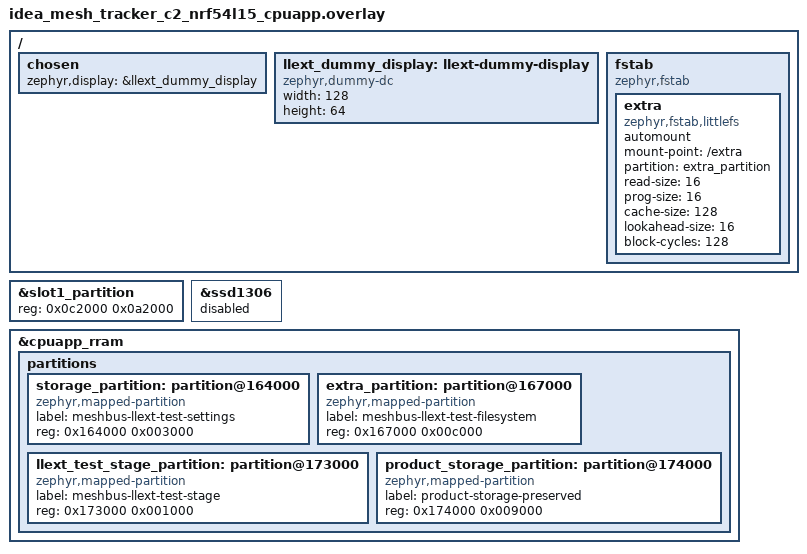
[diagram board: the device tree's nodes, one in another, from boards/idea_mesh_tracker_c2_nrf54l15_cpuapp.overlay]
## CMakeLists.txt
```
cmake_minimum_required(VERSION 3.20.0)

find_package(Zephyr REQUIRED HINTS $ENV{ZEPHYR_BASE})
project(mbs_llext_service_dut_test)

target_sources(app PRIVATE src/test_service_dut.c)
target_include_directories(app PRIVATE ../src)

set(llext_targets)
set(llext_outputs)


set(app_bin ${PROJECT_BINARY_DIR}/llext/mbs_app.mba)
set(app_inc ${ZEPHYR_BINARY_DIR}/include/generated/mbs_app.inc)
set(bad_symbol_app_bin ${PROJECT_BINARY_DIR}/llext/mbs_badsymapp.mba)
set(bad_symbol_app_inc ${ZEPHYR_BINARY_DIR}/include/generated/mbs_badsymapp.inc)

add_llext_target(mbs_app_ext
	OUTPUT ${app_bin}
	SOURCES ${CMAKE_CURRENT_SOURCE_DIR}/../src/app_ext.c
)
add_llext_target(mbs_badsymapp_ext
	OUTPUT ${bad_symbol_app_bin}
	SOURCES ${CMAKE_CURRENT_SOURCE_DIR}/../src/app_bad_symbol_ext.c
)

list(APPEND llext_targets mbs_app_ext mbs_badsymapp_ext)
list(APPEND llext_outputs ${app_bin} ${bad_symbol_app_bin})

generate_inc_file_for_target(app ${app_bin} ${app_inc})
generate_inc_file_for_target(app ${bad_symbol_app_bin} ${bad_symbol_app_inc})

foreach(llext_target ${llext_targets})
	if(TARGET ${llext_target}_llext_lib AND TARGET mbs_proto)
		add_dependencies(${llext_target}_llext_lib mbs_proto)
	endif()
endforeach()

foreach(ext ${llext_outputs})
	add_custom_command(
		OUTPUT ${ext}
		APPEND
		COMMAND ${CMAKE_OBJCOPY}
			--set-section-flags
			.meshbus.llext.meta=contents,readonly
			${ext}
	)
endforeach()
```

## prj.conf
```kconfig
# SPDX-FileCopyrightText: FoBE Studio
# SPDX-License-Identifier: Apache-2.0

CONFIG_ZTEST=y
CONFIG_ASSERT=y
CONFIG_LOG=y
CONFIG_LOG_MODE_IMMEDIATE=y

CONFIG_USERSPACE=n
CONFIG_MPU=n
CONFIG_ARM_MPU=n

CONFIG_MBS=y
CONFIG_MBS_LLEXT=y
CONFIG_MBS_LLEXT_DEFAULT_ENABLED=y
CONFIG_MBS_LLEXT_DYNAMIC_HEAP_MARGIN_PERCENT=5
CONFIG_MBS_LLEXT_TOTAL_HEAP_MAX_SIZE=98304

CONFIG_LLEXT=y
CONFIG_LLEXT_HEAP_DYNAMIC=y
CONFIG_LLEXT_SHELL=n

CONFIG_FILE_SYSTEM=y
CONFIG_FILE_SYSTEM_LITTLEFS=y
CONFIG_FS_LITTLEFS_FMP_DEV=y
CONFIG_FLASH=y
CONFIG_FLASH_MAP=y
CONFIG_FLASH_PAGE_LAYOUT=y

CONFIG_SETTINGS=y
CONFIG_SETTINGS_ZMS=y
CONFIG_SETTINGS_ZMS_LL_CACHE=y
CONFIG_SETTINGS_ZMS_LL_CACHE_SIZE=64
CONFIG_ZMS=y
CONFIG_ZMS_LOOKUP_CACHE=y
CONFIG_ZMS_LOOKUP_CACHE_SIZE=64
CONFIG_ZMS_LOOKUP_CACHE_FOR_SETTINGS=y

CONFIG_ZBUS_PRIORITY_BOOST=n
CONFIG_ZBUS_RUNTIME_OBSERVERS=y

CONFIG_HEAP_MEM_POOL_SIZE=98304
CONFIG_MAIN_STACK_SIZE=4096
CONFIG_SYSTEM_WORKQUEUE_STACK_SIZE=4096
CONFIG_ZTEST_STACK_SIZE=6144
CONFIG_THREAD_STACK_INFO=y
```

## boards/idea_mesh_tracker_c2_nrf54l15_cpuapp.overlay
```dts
/* Dedicated validation-device layout. See README.rst before flashing. */

/delete-node/ &storage_partition;

&slot1_partition {
	reg = <0x0c2000 0x0a2000>;
};

/* App-mode tests need ZUI types but do not exercise the physical display. */
&ssd1306 {
	status = "disabled";
};

&cpuapp_rram {
	partitions {
		storage_partition: partition@164000 {
			compatible = "zephyr,mapped-partition";
			label = "meshbus-llext-test-settings";
			reg = <0x164000 0x003000>;
		};

		extra_partition: partition@167000 {
			compatible = "zephyr,mapped-partition";
			label = "meshbus-llext-test-filesystem";
			reg = <0x167000 0x00c000>;
		};

		llext_test_stage_partition: partition@173000 {
			compatible = "zephyr,mapped-partition";
			label = "meshbus-llext-test-stage";
			reg = <0x173000 0x001000>;
		};

		product_storage_partition: partition@174000 {
			compatible = "zephyr,mapped-partition";
			label = "product-storage-preserved";
			reg = <0x174000 0x009000>;
		};
	};
};

/ {
	chosen {
		zephyr,display = &llext_dummy_display;
	};

	llext_dummy_display: llext-dummy-display {
		compatible = "zephyr,dummy-dc";
		width = <128>;
		height = <64>;
	};

	fstab: fstab {
		compatible = "zephyr,fstab";
		extra: extra {
			compatible = "zephyr,fstab,littlefs";
			automount;
			mount-point = "/extra";
			partition = <&extra_partition>;
			read-size = <16>;
			prog-size = <16>;
			cache-size = <128>;
			lookahead-size = <16>;
			block-cycles = <128>;
		};
	};
};
```

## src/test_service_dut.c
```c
/* SPDX-License-Identifier: Apache-2.0 */
/*
 * Copyright (c) 2026 FoBE Studio
 */

#include <errno.h>
#include <stdint.h>
#include <string.h>

#include <zephyr/devicetree.h>
#include <zephyr/fs/fs.h>
#include <zephyr/init.h>
#include <zephyr/kernel.h>
#include <zephyr/llext/symbol.h>
#include <llext/llext.h>
#include <zephyr/storage/flash_map.h>
#include <zephyr/sys/atomic.h>
#include <zephyr/ztest.h>

#include "app_api.h"

/* Mesh Probe R2 real-storage and real-loader service-DUT coverage. */

#define SETTINGS_PARTITION_NODE DT_NODELABEL(storage_partition)
#define EXTRA_PARTITION_NODE    DT_NODELABEL(extra_partition)
#define STAGE_PARTITION_NODE    DT_NODELABEL(llext_test_stage_partition)
#define PRODUCT_PARTITION_NODE  DT_NODELABEL(product_storage_partition)
#define SLOT0_PARTITION_NODE    DT_NODELABEL(slot0_partition)
#define SLOT1_PARTITION_NODE    DT_NODELABEL(slot1_partition)
#define RRAM_NODE               DT_MEM_FROM_PARTITION(EXTRA_PARTITION_NODE)

#define PARTITION_START(node_id) DT_REG_ADDR(node_id)
#define PARTITION_END(node_id)   (DT_REG_ADDR(node_id) + DT_REG_SIZE(node_id))
#define TEST_STAGE_MAGIC         0x4d424c58U
#define TEST_STAGE_PREPARED      1U
#define TEST_APP_ID              "mbs_app"
#define TEST_APP_PATH            "/extra/apps/mbs_app.mba"
#define BAD_APP_PATH             "/extra/apps/mbs_badsymapp.mba"

struct test_stage_record {
	uint32_t magic;
	uint32_t phase;
	uint32_t inverse;
	uint32_t reserved;
};

static struct test_stage_record test_stage;
static int test_storage_prepare_rc;
static atomic_t app_count;

BUILD_ASSERT(!IS_ENABLED(CONFIG_FLASH_SIMULATOR), "Mesh Probe R2 scenario must use real RRAM");
BUILD_ASSERT(DT_NODE_HAS_STATUS(SETTINGS_PARTITION_NODE, okay), "test settings missing");
BUILD_ASSERT(DT_NODE_HAS_STATUS(EXTRA_PARTITION_NODE, okay), "test filesystem missing");
BUILD_ASSERT(DT_NODE_HAS_STATUS(STAGE_PARTITION_NODE, okay), "test stage missing");
BUILD_ASSERT(DT_NODE_HAS_STATUS(PRODUCT_PARTITION_NODE, okay), "product guard missing");
BUILD_ASSERT(DT_REG_ADDR(SETTINGS_PARTITION_NODE) == 0x164000, "wrong test settings base");
BUILD_ASSERT(DT_REG_SIZE(SETTINGS_PARTITION_NODE) == 0x3000, "wrong test settings size");
BUILD_ASSERT(DT_REG_ADDR(EXTRA_PARTITION_NODE) == 0x167000, "wrong test FS base");
BUILD_ASSERT(DT_REG_SIZE(EXTRA_PARTITION_NODE) == 0xc000, "wrong test FS size");
BUILD_ASSERT(DT_REG_ADDR(STAGE_PARTITION_NODE) == 0x173000, "wrong stage base");
BUILD_ASSERT(DT_REG_SIZE(STAGE_PARTITION_NODE) == 0x1000, "wrong stage size");
BUILD_ASSERT(DT_REG_ADDR(PRODUCT_PARTITION_NODE) == 0x174000, "wrong product storage base");
BUILD_ASSERT(DT_REG_SIZE(PRODUCT_PARTITION_NODE) == 0x9000, "wrong product storage size");
BUILD_ASSERT(DT_PROP(RRAM_NODE, erase_block_size) == 4096, "unexpected erase alignment");
BUILD_ASSERT(DT_PROP(RRAM_NODE, write_block_size) == 16, "unexpected write alignment");
BUILD_ASSERT((sizeof(struct test_stage_record) % DT_PROP(RRAM_NODE, write_block_size)) == 0,
	     "test stage record is not write aligned");
BUILD_ASSERT(PARTITION_END(SLOT0_PARTITION_NODE) <= PARTITION_START(SLOT1_PARTITION_NODE),
	     "slot0 overlaps slot1");
BUILD_ASSERT(PARTITION_END(SLOT1_PARTITION_NODE) <= PARTITION_START(SETTINGS_PARTITION_NODE),
	     "slot1 overlaps test settings");
BUILD_ASSERT(PARTITION_END(SETTINGS_PARTITION_NODE) <= PARTITION_START(EXTRA_PARTITION_NODE),
	     "test settings overlaps filesystem");
BUILD_ASSERT(PARTITION_END(EXTRA_PARTITION_NODE) <= PARTITION_START(STAGE_PARTITION_NODE),
	     "test filesystem overlaps stage");
BUILD_ASSERT(PARTITION_END(STAGE_PARTITION_NODE) <= PARTITION_START(PRODUCT_PARTITION_NODE),
	     "stage overlaps product storage");
BUILD_ASSERT(PARTITION_END(PRODUCT_PARTITION_NODE) <= DT_REG_SIZE(RRAM_NODE),
	     "product storage exceeds CPUAPP RRAM");

int mbs_llext_test_hook(int event)
{
	switch (event) {
	case MBS_LLEXT_TEST_EVT_APP:
		atomic_inc(&app_count);
		return 0;
	default:
		return -EINVAL;
	}
}
EXPORT_SYMBOL(mbs_llext_test_hook);

static const uint8_t app_ext[] __aligned(4) = {
#include "mbs_app.inc"
};
static const uint8_t bad_symbol_app_ext[] __aligned(4) = {
#include "mbs_badsymapp.inc"
};

static uint32_t elapsed_us(uint64_t started)
{
	return (uint32_t)k_cyc_to_us_floor64(k_cycle_get_64() - started);
}

static int stage_write(void)
{
	const struct flash_area *area = NULL;
	struct test_stage_record next = {
		.magic = TEST_STAGE_MAGIC,
		.phase = TEST_STAGE_PREPARED,
		.inverse = ~TEST_STAGE_PREPARED,
	};
	int rc = flash_area_open(DT_FIXED_PARTITION_ID(STAGE_PARTITION_NODE), &area);

	if (rc == 0) {
		rc = flash_area_flatten(area, 0, area->fa_size);
	}
	if (rc == 0) {
		rc = flash_area_write(area, 0, &next, sizeof(next));
	}
	if (area != NULL) {
		flash_area_close(area);
	}
	if (rc == 0) {
		test_stage = next;
	}
	return rc;
}

static int stage_erase(void)
{
	const struct flash_area *area;
	int rc = flash_area_open(DT_FIXED_PARTITION_ID(STAGE_PARTITION_NODE), &area);

	if (rc == 0) {
		rc = flash_area_flatten(area, 0, area->fa_size);
		flash_area_close(area);
	}
	return rc;
}

static int flatten_partition(int partition_id)
{
	const struct flash_area *area;
	int rc = flash_area_open(partition_id, &area);

	if (rc == 0) {
		rc = flash_area_flatten(area, 0, area->fa_size);
		flash_area_close(area);
	}
	return rc;
}

static int llext_test_storage_prepare(void)
{
	int rc;

	rc = flatten_partition(DT_FIXED_PARTITION_ID(SETTINGS_PARTITION_NODE));
	if (rc == 0) {
		rc = flatten_partition(DT_FIXED_PARTITION_ID(EXTRA_PARTITION_NODE));
	}
	if (rc == 0) {
		rc = stage_write();
	}
	test_storage_prepare_rc = rc;
	return 0;
}

SYS_INIT(llext_test_storage_prepare, POST_KERNEL, 98);

static int write_file(const char *path, const uint8_t *data, size_t data_len)
{
	struct fs_file_t file;
	ssize_t wrote;
	int rc;

	fs_file_t_init(&file);
	rc = fs_open(&file, path, FS_O_CREATE | FS_O_TRUNC | FS_O_WRITE);
	if (rc != 0) {
		return rc;
	}
	wrote = fs_write(&file, data, data_len);
	if (wrote < 0) {
		(void)fs_close(&file);
		return (int)wrote;
	}
	if ((size_t)wrote != data_len) {
		(void)fs_close(&file);
		return -EIO;
	}
	return fs_close(&file);
}

static int ensure_directory(const char *path)
{
	struct fs_dirent entry;
	int rc = fs_stat(path, &entry);

	if (rc == 0) {
		return entry.type == FS_DIR_ENTRY_DIR ? 0 : -ENOTDIR;
	}
	if (rc != -ENOENT) {
		return rc;
	}

	rc = fs_mkdir(path);

	return rc == -EEXIST ? 0 : rc;
}

static void cleanup_file(const char *path)
{
	struct fs_dirent entry;
	int rc = fs_unlink(path);

	zassert_true(rc == 0 || rc == -ENOENT, "cleanup failed for %s: %d", path, rc);
	zassert_equal(fs_stat(path, &entry), -ENOENT, "cleanup left %s visible", path);
}

static void *suite_setup(void)
{
	zassert_ok(test_storage_prepare_rc, "test storage preparation failed: %d",
		   test_storage_prepare_rc);
	zassert_equal(test_stage.magic, TEST_STAGE_MAGIC, "test stage marker missing");
	zassert_ok(ensure_directory("/extra/apps"), "app directory create failed");
	atomic_clear(&app_count);

	zassert_ok(write_file(TEST_APP_PATH, app_ext, sizeof(app_ext)), "valid app seed failed");
	zassert_ok(write_file(BAD_APP_PATH, bad_symbol_app_ext, sizeof(bad_symbol_app_ext)),
		   "bad app seed failed");

	return NULL;
}

ZTEST(mbs_llext_service_dut, test_real_littlefs_app_runtime)
{
	struct mbs_llext_app_session *session = NULL;
	struct mbs_llext_app_info info;
	mbs_llext_app_entry_t entry;
	uint32_t first_load_us;
	uint32_t first_unload_us;
	uint64_t started;
	int rc;

	zassert_ok(mbs_llext_app_probe(TEST_APP_PATH, &info), "app probe failed");
	zassert_true(strcmp(info.id, TEST_APP_ID) == 0, "app id mismatch");
	zassert_true(strcmp(info.edk_version, "0.1.0") == 0,
		     "app EDK version mismatch");
	zassert_true(strcmp(info.target, CONFIG_BOARD_TARGET) == 0, "app target mismatch");

	started = k_cycle_get_64();
	zassert_ok(mbs_llext_app_load(TEST_APP_PATH, &session), "app load failed");
	first_load_us = elapsed_us(started);
	zassert_true(mbs_llext_runtime_busy(), "loaded app did not own runtime");
	zassert_ok(mbs_llext_app_get_entry(session, &entry), "app entry lookup failed");
	entry(NULL);
	zassert_equal(atomic_get(&app_count), 1, "app entry count mismatch");
	started = k_cycle_get_64();
	zassert_ok(mbs_llext_app_unload(session), "app unload failed");
	first_unload_us = elapsed_us(started);
	zassert_false(mbs_llext_runtime_busy(), "app unload left runtime busy");

	session = (void *)UINTPTR_MAX;
	rc = mbs_llext_app_load(BAD_APP_PATH, &session);
	zassert_equal(rc, -ENOEXEC, "missing-symbol app should fail load");
	zassert_is_null(session, "failed app load did not clear session");
	zassert_false(mbs_llext_runtime_busy(), "failed app load leaked runtime ownership");

	zassert_ok(mbs_llext_app_load(TEST_APP_PATH, &session),
		   "valid app did not recover after failed load");
	zassert_ok(mbs_llext_app_unload(session), "recovery app unload failed");
	zassert_false(mbs_llext_runtime_busy(), "recovery unload left runtime busy");

	cleanup_file(TEST_APP_PATH);
	cleanup_file(BAD_APP_PATH);
	zassert_ok(stage_erase(), "stage cleanup failed");
	printk("MBS_LLEXT_DUT_MEASUREMENT mode=app load_us=%u unload_us=%u\n", first_load_us,
	       first_unload_us);
	printk("MBS_LLEXT_DUT_RESULT pass mode=app entry_count=%ld recovery=1 cleanup=1\n",
	       (long)atomic_get(&app_count));
}

ZTEST_SUITE(mbs_llext_service_dut, NULL, suite_setup, NULL, NULL, NULL);
```
